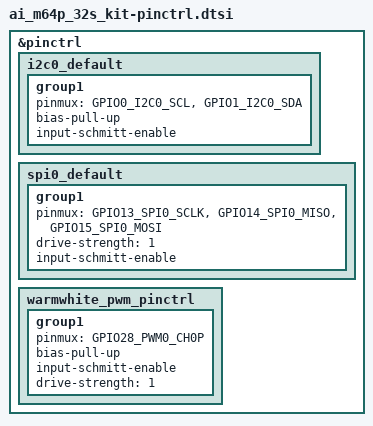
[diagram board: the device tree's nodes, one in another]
/*
 * Copyright (c) 2026 MASSDRIVER EI (massdriver.space)
 *
 * SPDX-License-Identifier: Apache-2.0
 */

&pinctrl {
	i2c0_default: i2c0_default {
		group1 {
			pinmux = <GPIO0_I2C0_SCL>,
				 <GPIO1_I2C0_SDA>;
			bias-pull-up;
			input-schmitt-enable;
		};
	};

	spi0_default: spi0_default {
		group1 {
			pinmux = <GPIO13_SPI0_SCLK>,
				 <GPIO14_SPI0_MISO>,
				 <GPIO15_SPI0_MOSI>;
			drive-strength = <1>;
			input-schmitt-enable;
		};
	};

	warmwhite_pwm_pinctrl: warmwhite_pwm_pinctrl {
		group1 {
			pinmux = <GPIO28_PWM0_CH0P>;
			bias-pull-up;
			input-schmitt-enable;
			drive-strength = <1>;
		};
	};
};
